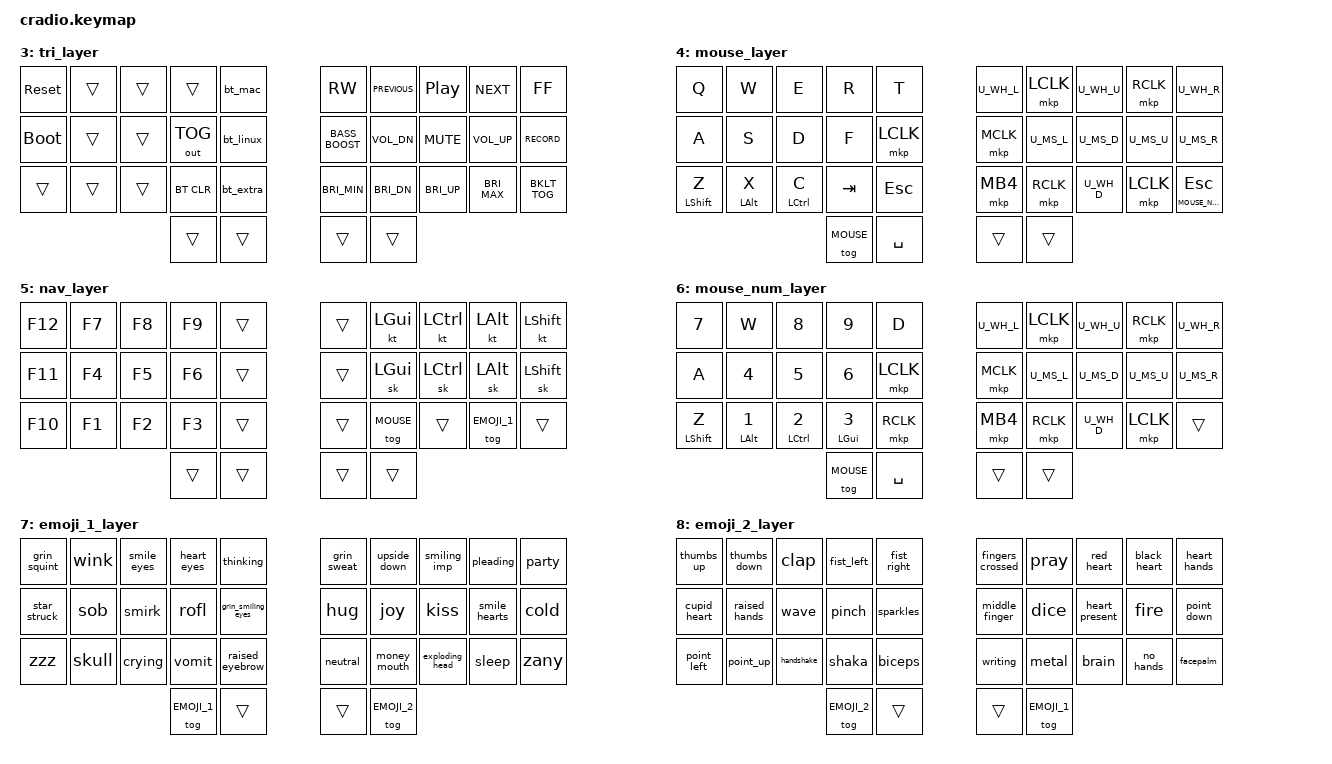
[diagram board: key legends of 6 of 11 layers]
// Copyright (c) 2022 The ZMK Contributors
// SPDX-License-Identifier: MIT

#include <behaviors.dtsi>
#include <dt-bindings/zmk/keys.h>
#include <dt-bindings/zmk/bt.h>
#include <dt-bindings/zmk/outputs.h>

#include "mouse.dtsi"
#include "emojis.dtsi"
#include "stenography.dtsi"

// BLUETOOTH PROFILE-BASED OS ADAPTATION
// Profile 0: macOS (Cmd on middle finger)
// Profile 1: Linux (Ctrl on middle finger)
// Profile 2: Available for third device

// Original home row mods macro (Linux/Windows style)
#define HRML(k1,k2,k3,k4) &ht LSHFT k1  &META LALT k2  &META LCTRL k3  &META LGUI k4
#define HRMR(k1,k2,k3,k4) &META RGUI k1  &META RCTRL k2  &META RALT k3  &ht RSHFT k4

// macOS-style home row mods (Cmd on middle finger)
#define HRML_MAC(k1,k2,k3,k4) &ht LSHFT k1  &META LALT k2  &META LGUI k3  &META LCTRL k4
#define HRMR_MAC(k1,k2,k3,k4) &META RCTRL k1  &META RGUI k2  &META RALT k3  &ht RSHFT k4

#define DEFAULT 0
#define NUMBER 1
#define SYMBOL 2
#define BLUETOOTH 3
#define MOUSE 4
#define NAV 5
#define MOUSE_NUM 6
#define EMOJI_1 7
#define EMOJI_2 8
#define MACOS_BASE 9
#define LINUX_BASE 10

#ifndef ZMK_MOUSE_DEFAULT_MOVE_VAL
#define ZMK_MOUSE_DEFAULT_MOVE_VAL 200
#endif

#ifndef ZMK_MOUSE_DEFAULT_SCRL_VAL
#define ZMK_MOUSE_DEFAULT_SCRL_VAL 30
#endif

&key_repeat {
    usage-pages = <HID_USAGE_KEY HID_USAGE_CONSUMER>;
};

/ {
    behaviors {
        ht: hold_tap {
            compatible = "zmk,behavior-hold-tap";
            #binding-cells = <2>;
            flavor = "tap-preferred";
            tapping-term-ms = <120>;
            quick-tap-ms = <90>;
            bindings = <&kp>, <&kp>;
        };
        
        META: meta_behavior {
            compatible = "zmk,behavior-hold-tap";
            #binding-cells = <2>;
            flavor = "tap-preferred";
            tapping-term-ms = <200>;
            quick-tap-ms = <120>;
            bindings = <&kp>, <&kp>;
        };

        // Bluetooth profile selectors with automatic layer switching
        bt_mac: bt_mac_profile {
            compatible = "zmk,behavior-macro";
            #binding-cells = <0>;
            bindings = <&bt BT_SEL 0>, <&to MACOS_BASE>;
        };

        bt_linux: bt_linux_profile {
            compatible = "zmk,behavior-macro";
            #binding-cells = <0>;
            bindings = <&bt BT_SEL 1>, <&to LINUX_BASE>;
        };

        bt_extra: bt_extra_profile {
            compatible = "zmk,behavior-macro";
            #binding-cells = <0>;
            bindings = <&bt BT_SEL 2>, <&to DEFAULT>;
        };
    };

    keymap {
        compatible = "zmk,keymap";
        
        // DEFAULT LAYER - Same as original
        qwerty_layer {
            bindings = <
        //╭──────────┬──────────┬──────────┬──────────┬──────────╮   ╭──────────┬──────────┬──────────┬──────────┬──────────╮
        //│  Q       │  W       │  E       │  R       │  T       │   │  Y       │  U       │  I       │  O       │  P       │
            &kp Q      &kp W      &kp E      &kp R      &kp T          &kp Y      &kp U      &kp I      &kp O      &kp P
        //├──────────┼──────────┼──────────┼──────────┼──────────┤   ├──────────┼──────────┼──────────┼──────────┼──────────┤
        //│  A       │  S       │  D       │  F       │  G       │   │  H       │  J       │  K       │  L       │ ' "      │
            HRML(A,        S,         D,         F)     &kp G          &kp H      HRMR(J,        K,         L,        SQT)
        //├──────────┼──────────┼──────────┼──────────┼──────────┤   ├──────────┼──────────┼──────────┼──────────┼──────────┤
        //│  Z       │  X       │  C       │  V       │  B       │   │  N       │  M       │ ESCAPE   │ REPEAT   │ / ?      │
            &kp Z      &kp X      &kp C      &kp V      &kp B         &kp N      &kp M    &kp ESC  &key_repeat  &kp FSLH
        //╰──────────┴──────────┴──────────┼──────────┼──────────┤   ├──────────┼──────────┼──────────┴──────────┴──────────╯
                                           &lt SYMBOL TAB &lt NAV SPACE &lt MOUSE ENTER  &lt NUMBER BSPC
        //                                 ╰──────────┴──────────╯   ╰──────────┴──────────╯
            >; 
        };

        right_layer {
            bindings = < 
        //╭──────────┬──────────┬──────────┬──────────┬──────────╮   ╭──────────┬──────────┬──────────┬──────────┬──────────╮
        //│   GT     │  7       │  8       │  9       │  =       │   │ HOME     │ PAGE DN  │ PAGE UP  │ END      │  :       │
           &kp GT   &kp N7     &kp N8     &kp N9     &kp EQUAL     &kp HOME   &kp PG_DN  &kp PG_UP  &kp END    &kp COLON
        //├──────────┼──────────┼──────────┼──────────┼──────────┤   ├──────────┼──────────┼──────────┼──────────┼──────────┤
        //│ 0        │  4       │  5       │  6       │  -       │   │ LEFT     │ DOWN     │ UP       │ RIGHT    │  ;       │
            HRML(N0,    N4,         N5,         N6)     &kp MINUS         &kp LARW  HRMR(DARW,   UARW,       RARW,      SEMI)
        //├──────────┼──────────┼──────────┼──────────┼──────────┤   ├──────────┼──────────┼──────────┼──────────┼──────────┤
        //│  LT      │  1       │  2       │  3       │  +       │   │  INSERT  │  DELETE  │ ESCAPE   │  ENTER   │  .       │
           &kp LT   &kp N1     &kp N2     &kp N3     &kp PLUS         &kp INSERT &kp DELETE &trans    &kp ENTER  &kp DOT
        //╰──────────┴──────────┴──────────┼──────────┼──────────┤   ├──────────┼──────────┼──────────┴──────────┴──────────╯
                                            &key_repeat &lt BLUETOOTH SPACE     &trans    &trans
        //                                 ╰──────────┴──────────╯   ╰──────────┴──────────╯
            >;
        };
        
        left_layer {
            bindings = <
        //╭──────────┬──────────┬──────────┬──────────┬──────────╮   ╭──────────┬──────────┬──────────┬──────────┬──────────╮
        //│   {      │  &       │  *       │  (       │   [      │   │  ;       │  =       │  LT      │  GT      │  ~       
            &kp LBRC    &kp AMPS  &kp ASTRK  &kp LPAR  &kp LBKT       &kp SEMI  &kp EQUAL   &kp LT   &kp GT   &kp TILDE
        //├──────────┼──────────┼──────────┼──────────┼──────────┤   ├──────────┼──────────┼──────────┼──────────┼──────────┤
        //│  )       │  $       │  %       │  ^       │  _       │   │  /       │  ,       │  |       │  \       │  `       │
           HRML(RPAR,  DLLR,       PRCNT,     CARET)    &kp UNDER      &kp FSLH  HRMR(COMMA,  PIPE,     BSLH,     GRAVE)
        //├──────────┼──────────┼──────────┼──────────┼──────────┤   ├──────────┼──────────┼──────────┼──────────┼──────────┤
        //│  ]       │  !       │  @       │ #        │   }      │   │  -       │  .       │ ESCAPE   │ SPACE    │          │
            &kp RBKT  &kp EXCL    &kp AT     &kp HASH    &kp RBRC     &kp MINUS   &kp DOT    &trans     &kp SPACE  &trans
        //╰──────────┴──────────┴──────────┼──────────┼──────────┤   ├──────────┼──────────┼──────────┴──────────┴──────────╯
                                             &trans     &trans      &lt MOUSE ENTER &key_repeat
        //                                 ╰──────────┴──────────╯   ╰──────────┴──────────╯
            >;
        };

        // Modified Bluetooth layer with OS profile switching
        tri_layer {
            bindings = <
        //╭──────────┬──────────┬──────────┬──────────┬──────────╮   ╭──────────┬──────────┬──────────┬──────────┬──────────╮
        //│ RESET    │          │          │          │BT 0 macOS│   │ BACKWARD │ PREVIOUS │PLAY/PAUSE│ NEXT     │ FORWARD  │
           &sys_reset  &trans     &trans     &trans     &bt_mac       &kp C_RW   &kp C_PREVIOUS &kp C_PP &kp C_NEXT &kp C_FF
        //├──────────┼──────────┼──────────┼──────────┼──────────┤   ├──────────┼──────────┼──────────┼──────────┼──────────┤
        //│BOOTLOADER│          │          │          │BT 1 Linux│   │   BASS   │ VOL DN   │  MUTE    │  VOL UP  │  RECORD  │
          &bootloader  &trans     &trans  &out OUT_TOG  &bt_linux     &kp C_BASS_BOOST &kp C_VOL_DN &kp C_MUTE  &kp C_VOL_UP  &kp C_RECORD
        //├──────────┼──────────┼──────────┼──────────┼──────────┤   ├──────────┼──────────┼──────────┼──────────┼──────────┤
        //│          │          │          │ CLEAR BT │BT 2 Extra│   │ BRI MIN  │ BRI DN   │ BRI UP   │ BRI MAX  │ BKLT TOG │
            &trans     &trans    &trans     &bt BT_CLR  &bt_extra     &kp C_BRI_MIN &kp C_BRI_DN &kp C_BRI_UP &kp C_BRI_MAX &kp C_BKLT_TOG
        //╰──────────┴──────────┴──────────┼──────────┼──────────┤   ├──────────┼──────────┼──────────┴──────────┴──────────╯
                                             &trans     &trans         &trans     &trans
        //                                 ╰──────────┴──────────╯   ╰──────────┴──────────╯
            >;
        };

        mouse_layer {
            bindings = <
        //╭──────────┬──────────┬──────────┬──────────┬──────────╮   ╭──────────┬──────────┬──────────┬──────────┬──────────╮
        //│          │          │          │          │          │   │          │          │          │          │          │
           &kp Q      &kp W      &kp E      &kp R      &kp T          U_WH_L     &mkp LCLK  U_WH_U     &mkp RCLK  U_WH_R
        //├──────────┼──────────┼──────────┼──────────┼──────────┤   ├──────────┼──────────┼──────────┼──────────┼──────────┤
        //│          │          │          │          │          │   │          │          │          │          │          │
           &kp A      &kp S      &kp D      &kp F      &mkp LCLK      &mkp MCLK  U_MS_L     U_MS_D     U_MS_U     U_MS_R 
        //├──────────┼──────────┼──────────┼──────────┼──────────┤   ├──────────┼──────────┼──────────┼──────────┼──────────┤
        //│          │          │          │          │          │   │          │          │          │          │          │
          &ht LSHFT Z &ht LALT X &ht LCTRL C &kp TAB   &kp ESC       &mkp MB4   &mkp RCLK  U_WH_D     &mkp LCLK  &lt MOUSE_NUM ESC
        //╰──────────┴──────────┴──────────┼──────────┼──────────┤   ├──────────┼──────────┼──────────┴──────────┴──────────╯
                                            &tog MOUSE &kp SPACE      &trans     &trans
        //                                 ╰──────────┴──────────╯   ╰──────────┴──────────╯
            >;
        };
        
        nav_layer {
            bindings = <
        //╭──────────┬──────────┬──────────┬──────────┬──────────╮   ╭──────────┬──────────┬──────────┬──────────┬──────────╮
        //│          │          │          │          │          │   │          │          │          │          │          │
           &kp F12    &kp F7     &kp F8     &kp F9     &trans         &trans     &kt LGUI   &kt LCTRL  &kt LALT   &kt LSHFT
        //├──────────┼──────────┼──────────┼──────────┼──────────┤   ├──────────┼──────────┼──────────┼──────────┼──────────┤
        //           │          │          │          │          │   │          │          │          │          │          │
           &kp F11    &kp F4    &kp F5      &kp F6     &trans         &trans     &sk LGUI   &sk LCTRL  &sk LALT   &sk LSHFT 
        //├──────────┼──────────┼──────────┼──────────┼──────────┤   ├──────────┼──────────┼──────────┼──────────┼──────────┤
        //│          │          │          │          │          │   │          │          │          │          │          │
           &kp F10    &kp F1    &kp F2      &kp F3     &trans         &trans     &tog MOUSE  &trans    &tog EMOJI_1  &trans
        //╰──────────┴──────────┴──────────┼──────────┼──────────┤   ├──────────┼──────────┼──────────┴──────────┴──────────╯
                                            &trans     &trans         &trans     &trans
        //                                 ╰──────────┴──────────╯   ╰──────────┴──────────╯
            >;
        };

        mouse_num_layer {
            bindings = <
        //╭──────────┬──────────┬──────────┬──────────┬──────────╮   ╭──────────┬──────────┬──────────┬──────────┬──────────╮
        //│          │          │          │          │          │   │          │          │          │          │          │
           &kp N7      &kp W     &kp N8     &kp N9     &kp D          U_WH_L     &mkp LCLK  U_WH_U     &mkp RCLK  U_WH_R
        //├──────────┼──────────┼──────────┼──────────┼──────────┤   ├──────────┼──────────┼──────────┼──────────┼──────────┤
        //│          │          │          │          │          │   │          │          │          │          │          │
           &kp A      &kp N4     &kp N5     &kp N6     &mkp LCLK      &mkp MCLK  U_MS_L     U_MS_D     U_MS_U     U_MS_R 
        //├──────────┼──────────┼──────────┼──────────┼──────────┤   ├──────────┼──────────┼──────────┼──────────┼──────────┤
        //│          │          │          │          │          │   │          │          │          │          │          │
         &ht LSHFT Z &META LALT N1 &META LCTRL N2 &META LGUI N3 &mkp RCLK   &mkp MB4   &mkp RCLK  U_WH_D     &mkp LCLK  &trans
        //╰──────────┴──────────┴──────────┼──────────┼──────────┤   ├──────────┼──────────┼──────────┴──────────┴──────────╯
        &tog MOUSE &kp SPACE      &trans     &trans
        //                                 ╰──────────┴──────────╯   ╰──────────┴──────────╯
            >;
        };

        emoji_1_layer {
          bindings = <
            //╭──────────┬──────────┬──────────┬──────────┬──────────╮   ╭──────────┬──────────┬──────────┬──────────┬──────────╮
            //│    😆    │    😉    │    😊    │    😍    │    🤔    │   │    😅    │    🙃    │    😈    │    🥺    │    🥳    │
            &grin_squint &wink      &smile_eyes &heart_eyes &thinking &grin_sweat &upside_down &smiling_imp &pleading &party
            //├──────────┼──────────┼──────────┼──────────┼──────────┤   ├──────────┼──────────┼──────────┼──────────┼──────────┤
            //│    🤩    │    😭    │    😏    │    🤣    │    😄    │   │    🤗    │    😂    │    😘    │    🥰    │    🥶    │
            &star_struck &sob       &smirk      &rofl      &grin_smiling_eyes &hug      &joy      &kiss     &smile_hearts &cold
            //├──────────┼──────────┼──────────┼──────────┼──────────┤   ├──────────┼──────────┼──────────┼──────────┼──────────┤
            //│    💤    │    💀    │    😢    │    🤮    │    🤨    │   │    😐    │    🤑    │    🤯    │    😴    │    🤪    │
               &zzz       &skull    &crying    &vomit     &raised_eyebrow &neutral  &money_mouth &exploding_head &sleep &zany
            //╰──────────┴──────────┴──────────┼──────────┼──────────┤   ├──────────┼──────────┼──────────┴──────────┴──────────╯
                                               &tog EMOJI_1 &trans        &trans     &tog EMOJI_2     
            //                                 ╰──────────┴──────────╯   ╰──────────┴──────────╯
            >;
        };

        emoji_2_layer {
            bindings = <
                //╭──────────┬──────────┬──────────┬──────────┬──────────╮   ╭──────────┬──────────┬──────────┬──────────┬──────────╮
                //│    👍    │    👎    │    👏    │    🤛    │    🤜    │   │    🤞    │    🙏    │    ❤️    │    🖤    │    🫶    │
                  &thumbs_up  &thumbs_down &clap    &fist_left &fist_right  &fingers_crossed &pray &red_heart &black_heart &heart_hands
                //├──────────┼──────────┼──────────┼──────────┼──────────┤   ├──────────┼──────────┼──────────┼──────────┼──────────┤
                //│    💖    │    🙌    │    👋    │    🤌    │    ✨    │   │    🖕    │    🎲    │    💖    │    🔥    │    👇    │
                  &cupid_heart &raised_hands &wave  &pinch    &sparkles    &middle_finger   &dice &heart_present &fire   &point_down
                //├──────────┼──────────┼──────────┼──────────┼──────────┤   ├──────────┼──────────┼──────────┼──────────┼──────────┤
                //│    👈    │   	☝   │    🤝    │    🤙    │    💪    │   │    ✍️     │    🤘    │    🧠    │    🙅    │    🤦    │
                  &point_left  &point_up  &handshake &shaka    &biceps        &writing   &metal   &brain     &no_hands   &facepalm
                //╰──────────┴──────────┴──────────┼──────────┼──────────┤   ├──────────┼──────────┼──────────┴──────────┴──────────╯
                                                 &tog EMOJI_2 &trans     &trans     &tog EMOJI_1     
                //                               ╰──────────┴──────────╯   ╰──────────┴──────────╯
            >;
        };

        // macOS-optimized layer (Profile 0)
        macos_base_layer {
            bindings = <
        //╭──────────┬──────────┬──────────┬──────────┬──────────╮   ╭──────────┬──────────┬──────────┬──────────┬──────────╮
        //│  Q       │  W       │  E       │  R       │  T       │   │  Y       │  U       │  I       │  O       │  P       │
            &kp Q      &kp W      &kp E      &kp R      &kp T          &kp Y      &kp U      &kp I      &kp O      &kp P
        //├──────────┼──────────┼──────────┼──────────┼──────────┤   ├──────────┼──────────┼──────────┼──────────┼──────────┤
        //│  A       │  S       │  D       │  F       │  G       │   │  H       │  J       │  K       │  L       │ ' "      │
        //│ Shift    │ Option   │ Cmd      │ Ctrl     │          │   │          │ Ctrl     │ Cmd      │ Option   │ Shift    │
            HRML_MAC(A,    S,         D,         F)     &kp G          &kp H      HRMR_MAC(J,    K,         L,        SQT)
        //├──────────┼──────────┼──────────┼──────────┼──────────┤   ├──────────┼──────────┼──────────┼──────────┼──────────┤
        //│  Z       │  X       │  C       │  V       │  B       │   │  N       │  M       │ ESCAPE   │ REPEAT   │ / ?      │
            &kp Z      &kp X      &kp C      &kp V      &kp B         &kp N      &kp M    &kp ESC  &key_repeat  &kp FSLH
        //╰──────────┴──────────┴──────────┼──────────┼──────────┤   ├──────────┼──────────┼──────────┴──────────┴──────────╯
                                           &lt SYMBOL TAB &lt NAV SPACE &lt MOUSE ENTER  &lt NUMBER BSPC
        //                                 ╰──────────┴──────────╯   ╰──────────┴──────────╯
            >; 
        };

        // Linux-optimized layer (Profile 1) - identical to default
        linux_base_layer {
            bindings = <
        //╭──────────┬──────────┬──────────┬──────────┬──────────╮   ╭──────────┬──────────┬──────────┬──────────┬──────────╮
        //│  Q       │  W       │  E       │  R       │  T       │   │  Y       │  U       │  I       │  O       │  P       │
            &kp Q      &kp W      &kp E      &kp R      &kp T          &kp Y      &kp U      &kp I      &kp O      &kp P
        //├──────────┼──────────┼──────────┼──────────┼──────────┤   ├──────────┼──────────┼──────────┼──────────┼──────────┤
        //│  A       │  S       │  D       │  F       │  G       │   │  H       │  J       │  K       │  L       │ ' "      │
        //│ Shift    │ Alt      │ Ctrl     │ Super    │          │   │          │ Super    │ Ctrl     │ Alt      │ Shift    │
            HRML(A,        S,         D,         F)     &kp G          &kp H      HRMR(J,        K,         L,        SQT)
        //├──────────┼──────────┼──────────┼──────────┼──────────┤   ├──────────┼──────────┼──────────┼──────────┼──────────┤
        //│  Z       │  X       │  C       │  V       │  B       │   │  N       │  M       │ ESCAPE   │ REPEAT   │ / ?      │
            &kp Z      &kp X      &kp C      &kp V      &kp B         &kp N      &kp M    &kp ESC  &key_repeat  &kp FSLH
        //╰──────────┴──────────┴──────────┼──────────┼──────────┤   ├──────────┼──────────┼──────────┴──────────┴──────────╯
                                           &lt SYMBOL TAB &lt NAV SPACE &lt MOUSE ENTER  &lt NUMBER BSPC
        //                                 ╰──────────┴──────────╯   ╰──────────┴──────────╯
            >; 
        };
    };
};
